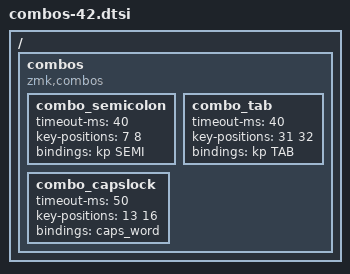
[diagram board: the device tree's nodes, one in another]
/*

KEY POSITIONS

 -- from https://github.com/caksoylar/zmk-config/blob/main/config/combos.dtsi

  ╭────────────────────────╮ ╭────────────────────────╮
  │  0   1   2   3   4   5 │ │  6   7   8   9  10  11 │
  │ 12  13  14  15  16  17 │ │ 18  19  20  21  22  23 │
  │ 24  25  26  27  28  29 │ │ 30  31  32  33  34  35 │
  ╰───────────╮ 36  37  38 │ │ 39  40  41 ╭───────────╯
              ╰────────────╯ ╰────────────╯
*/

#include <dt-bindings/zmk/keys.h>
#define COMBO(NAME, BINDINGS, KEYPOS, LAYERS, TERM) \
        combo_##NAME { \
            timeout-ms = <TERM>; \
            bindings = <BINDINGS>; \
            key-positions = <KEYPOS>; \
            layers = <LAYERS>; \
        };

/ {
    combos {
        compatible = "zmk,combos";
        combo_semicolon {
            timeout-ms = <40>;
            key-positions = <7 8>;
            bindings = <&kp SEMI>;
        };
        combo_tab {
           timeout-ms = <40>;
           key-positions = <31 32>;
           bindings = <&kp TAB>;
        };

        combo_capslock {
            timeout-ms = <50>;
            key-positions = <13 16>;
            bindings = <&caps_word>;
       };
    };
};
